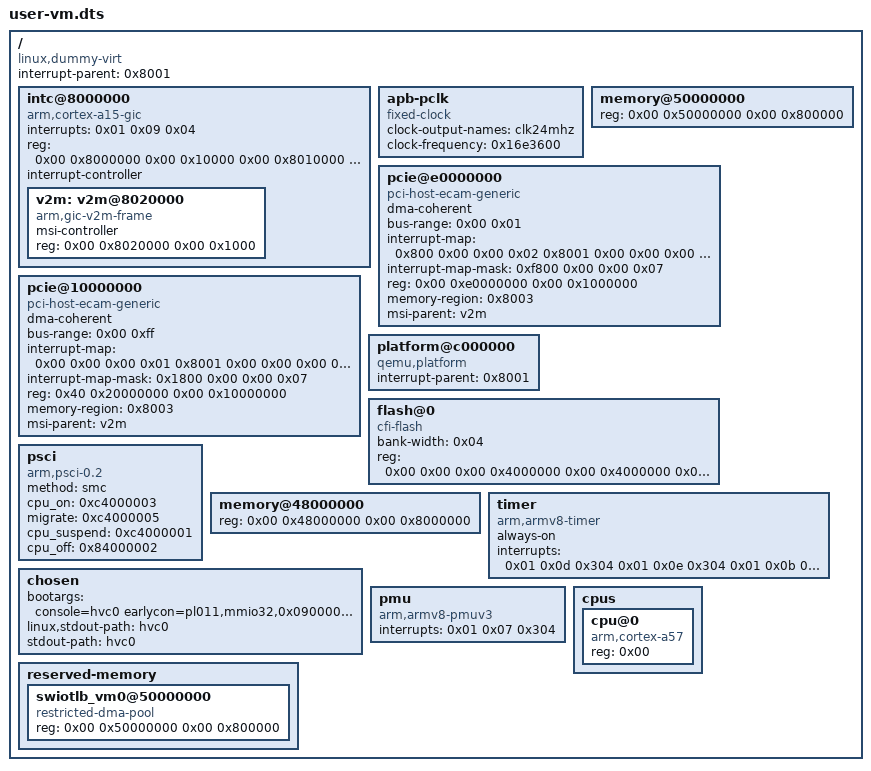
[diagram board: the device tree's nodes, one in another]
/dts-v1/;

/ {
        #address-cells = <0x02>;
        #size-cells = <0x02>;
        interrupt-parent = <0x8001>;
        compatible = "linux,dummy-virt";

        intc@8000000 {
                #address-cells = <0x02>;
                interrupts = <0x01 0x09 0x04>;
                #size-cells = <0x02>;
                compatible = "arm,cortex-a15-gic";
                ranges;
                #interrupt-cells = <0x03>;
                reg = <0x00 0x8000000 0x00 0x10000 0x00 0x8010000 0x00 0x10000 0x00 0x8030000 0x00 0x10000 0x00 0x8040000 0x00 0x10000>;
                phandle = <0x8001>;
                interrupt-controller;

                v2m: v2m@8020000 {
                        msi-controller;
                        compatible = "arm,gic-v2m-frame";
                        reg = <0x00 0x8020000 0x00 0x1000>;
                };
        };

        apb-pclk {
                clock-output-names = "clk24mhz";
                #clock-cells = <0x00>;
                clock-frequency = <0x16e3600>;
                compatible = "fixed-clock";
                phandle = <0x8000>;
        };

        memory@50000000 {
                device_type = "memory";
                reg = <0x00 0x50000000 0x00 0x800000>;
        };

        pcie@e0000000 {
                #address-cells = <0x03>;
                dma-coherent;
                bus-range = <0x00 0x01>;
                // PCI address + Pin + Interrupt Controller Handle + Interrupt Controller Data
                //   PCI address -> 3 cells (#address-cells of the pci node)
                //   Pin -> 1 cell
                //   Intc handle -> 3 (#interrupt-cells of the intc)
                //   Intc data -> 3 cells
                //              |PCI address    |Pin |Intc handle     |Intc data     |
                interrupt-map = <0x800 0x00 0x00 0x02 0x8001 0x00 0x00 0x00 0x71 0x04
                        0x1000 0x00 0x00 0x03 0x8001 0x00 0x00 0x00 0x72 0x04
                        0x1800 0x00 0x00 0x04 0x8001 0x00 0x00 0x00 0x73 0x04
                        0x2000 0x00 0x00 0x01 0x8001 0x00 0x00 0x00 0x70 0x04
                        >;
                #size-cells = <0x02>;
                device_type = "pci";
                interrupt-map-mask = <0xf800 0x00 0x00 0x07>;
                compatible = "pci-host-ecam-generic";
                // | PCI Address | CPU Address | PCI size |
                //   PCI Address -> 3 (PCI node #address-cells)
                //   CPU Address -> 2 (parent #address-cells)
                //   PCI Size -> 2 (PCI node #size-cells)
                ranges = <0x1000000 0x00 0x00 0x00 0xe1000000 0x00 0x10000
                        0x3000000 0x00 0xc0000000 0x00 0xc0000000 0x00 0x20000000>;
                #interrupt-cells = <0x01>;
                reg = <0x00 0xe0000000 0x00 0x1000000>;

                /* use swiotlb */
                memory-region = <0x8003>;
                msi-parent = <&v2m>;
        };

        pcie@10000000 {
                #address-cells = <0x03>;
                dma-coherent;
                bus-range = <0x00 0xff>;
                interrupt-map = <0x00 0x00 0x00 0x01 0x8001 0x00 0x00 0x00 0x03 0x04
                        0x00 0x00 0x00 0x02 0x8001 0x00 0x00 0x00 0x04 0x04
                        0x00 0x00 0x00 0x03 0x8001 0x00 0x00 0x00 0x05 0x04
                        0x00 0x00 0x00 0x04 0x8001 0x00 0x00 0x00 0x06 0x04
                        0x800 0x00 0x00 0x01 0x8001 0x00 0x00 0x00 0x04 0x04
                        0x800 0x00 0x00 0x02 0x8001 0x00 0x00 0x00 0x05 0x04
                        0x800 0x00 0x00 0x03 0x8001 0x00 0x00 0x00 0x06 0x04
                        0x800 0x00 0x00 0x04 0x8001 0x00 0x00 0x00 0x03 0x04
                        0x1000 0x00 0x00 0x01 0x8001 0x00 0x00 0x00 0x05 0x04
                        0x1000 0x00 0x00 0x02 0x8001 0x00 0x00 0x00 0x06 0x04
                        0x1000 0x00 0x00 0x03 0x8001 0x00 0x00 0x00 0x03 0x04
                        0x1000 0x00 0x00 0x04 0x8001 0x00 0x00 0x00 0x04 0x04
                        0x1800 0x00 0x00 0x01 0x8001 0x00 0x00 0x00 0x06 0x04
                        0x1800 0x00 0x00 0x02 0x8001 0x00 0x00 0x00 0x03 0x04
                        0x1800 0x00 0x00 0x03 0x8001 0x00 0x00 0x00 0x04 0x04
                        0x1800 0x00 0x00 0x04 0x8001 0x00 0x00 0x00 0x05 0x04>;
                #size-cells = <0x02>;
                device_type = "pci";
                interrupt-map-mask = <0x1800 0x00 0x00 0x07>;
                compatible = "pci-host-ecam-generic";
                ranges = <0x1000000 0x00 0x00 0x00 0x3eff0000 0x00 0x10000
                        0x2000000 0x00 0x10000000 0x00 0x10000000 0x00 0x2eff0000
                        0x3000000 0x80 0x00 0x80 0x00 0x80 0x00>;
                #interrupt-cells = <0x01>;
                reg = <0x40 0x20000000 0x00 0x10000000>;
                memory-region = <0x8003>;

                msi-parent = <&v2m>;
        };
        platform@c000000 {
                #address-cells = <0x01>;
                #size-cells = <0x01>;
                interrupt-parent = <0x8001>;
                compatible = "qemu,platform\0simple-bus";
                ranges = <0x00 0x00 0xc000000 0x2000000>;
        };

        flash@0 {
                bank-width = <0x04>;
                compatible = "cfi-flash";
                reg = <0x00 0x00 0x00 0x4000000 0x00 0x4000000 0x00 0x4000000>;
        };

        psci {
                method = "smc";
                compatible = "arm,psci-0.2\0arm,psci";
                cpu_on = <0xc4000003>;
                migrate = <0xc4000005>;
                cpu_suspend = <0xc4000001>;
                cpu_off = <0x84000002>;
        };

        memory@48000000 {
                device_type = "memory";
                reg = <0x00 0x48000000 0x00 0x8000000>;
        };

        timer {
                always-on;
                interrupts = <0x01 0x0d 0x304 0x01 0x0e 0x304 0x01 0x0b 0x304 0x01 0x0a 0x304>;
                compatible = "arm,armv8-timer\0arm,armv7-timer";
        };

        chosen {
                bootargs = "console=hvc0 earlycon=pl011,mmio32,0x09000000 root=/dev/vda1 rw debug loglevel=8 initcall_blacklist=clk_disable_unused maxcpus=1";
                linux,stdout-path = "hvc0";
                stdout-path = "hvc0";
        };

        pmu {
                interrupts = <0x01 0x07 0x304>;
                compatible = "arm,armv8-pmuv3";
        };

        cpus {
                #address-cells = <0x01>;
                #size-cells = <0x00>;

                cpu@0 {
                        device_type = "cpu";
                        compatible = "arm,cortex-a57";
                        reg = <0x00>;
                };
        };

        reserved-memory {
                #address-cells = <0x02>;
                #size-cells = <0x02>;
                ranges;

                swiotlb_vm0@50000000 {
                        compatible = "restricted-dma-pool";
                        reg = <0x00 0x50000000 0x00 0x800000>;
                        phandle = <0x8003>;
                };
        };
};
